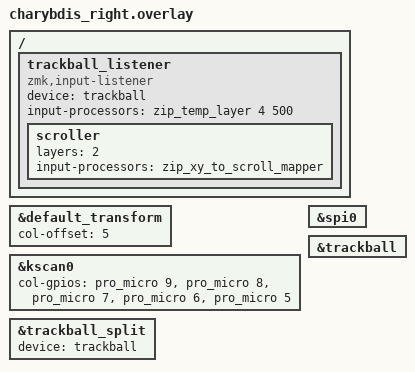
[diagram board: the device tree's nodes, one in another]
#include "charybdis.dtsi" // Notice that the main dtsi files are included in the overlay.
#include "pmw3610.dtsi"

&default_transform {
	col-offset = <5>;
};


&kscan0 {
    col-gpios
        = <&pro_micro 9 GPIO_ACTIVE_HIGH>
        , <&pro_micro 8 GPIO_ACTIVE_HIGH>
        , <&pro_micro 7 GPIO_ACTIVE_HIGH>
        , <&pro_micro 6 GPIO_ACTIVE_HIGH>
        , <&pro_micro 5 GPIO_ACTIVE_HIGH>
        ;
};

&spi0 {
    status = "okay";
};


&trackball {
    status = "okay";
};

&trackball_split {
	device = <&trackball>;
};

/ {
  trackball_listener {
    compatible = "zmk,input-listener";
    status = "okay";
    scroller {
		layers = <2>;
		input-processors = <&zip_xy_to_scroll_mapper>;
	};
    device = <&trackball>;
    input-processors =
        <&zip_temp_layer 4 500>;//activate layer 3 within 500ms of the trackball moving
  };
};

